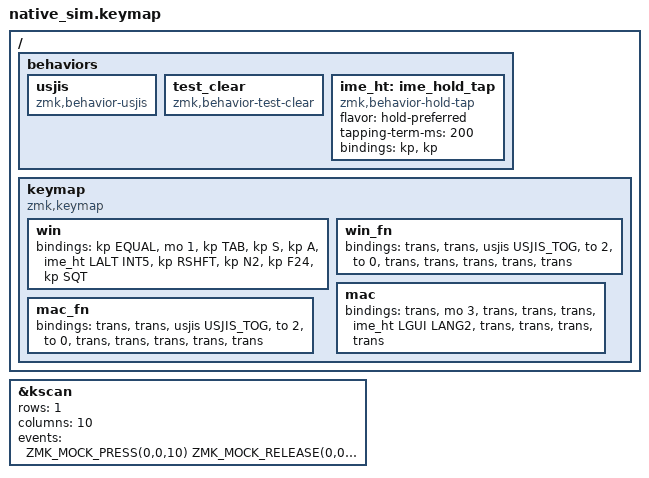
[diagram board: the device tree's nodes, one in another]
/* Generated by tests/zmk/generate.py; do not edit. */
#include <dt-bindings/zmk/keys.h>
#include <behaviors.dtsi>
#include <dt-bindings/zmk/kscan_mock.h>
#include <dt-bindings/zmk/usjis.h>

&kscan {
    rows = <1>;
    columns = <10>;
    events = <
        ZMK_MOCK_PRESS(0,0,10)
        ZMK_MOCK_RELEASE(0,0,10)
        ZMK_MOCK_PRESS(0,1,10)
        ZMK_MOCK_PRESS(0,2,10)
        ZMK_MOCK_RELEASE(0,2,10)
        ZMK_MOCK_RELEASE(0,1,10)
        ZMK_MOCK_PRESS(0,0,10)
        ZMK_MOCK_RELEASE(0,0,10)
        ZMK_MOCK_PRESS(0,6,10)
        ZMK_MOCK_PRESS(0,7,10)
        ZMK_MOCK_RELEASE(0,7,10)
        ZMK_MOCK_RELEASE(0,6,10)
        ZMK_MOCK_PRESS(0,8,10)
        ZMK_MOCK_RELEASE(0,8,10)
        ZMK_MOCK_PRESS(0,1,10)
        ZMK_MOCK_PRESS(0,3,10)
        ZMK_MOCK_RELEASE(0,3,10)
        ZMK_MOCK_RELEASE(0,1,10)
        ZMK_MOCK_PRESS(0,0,10)
        ZMK_MOCK_RELEASE(0,0,10)
        ZMK_MOCK_PRESS(0,6,10)
        ZMK_MOCK_PRESS(0,7,10)
        ZMK_MOCK_RELEASE(0,7,10)
        ZMK_MOCK_RELEASE(0,6,10)
        ZMK_MOCK_PRESS(0,9,10)
        ZMK_MOCK_RELEASE(0,9,10)
        ZMK_MOCK_PRESS(0,8,10)
        ZMK_MOCK_RELEASE(0,8,10)
        ZMK_MOCK_PRESS(0,1,10)
        ZMK_MOCK_PRESS(0,2,10)
        ZMK_MOCK_RELEASE(0,2,10)
        ZMK_MOCK_RELEASE(0,1,10)
        ZMK_MOCK_PRESS(0,0,10)
        ZMK_MOCK_RELEASE(0,0,10)
        ZMK_MOCK_PRESS(0,1,10)
        ZMK_MOCK_PRESS(0,2,10)
        ZMK_MOCK_RELEASE(0,2,10)
        ZMK_MOCK_RELEASE(0,1,10)
        ZMK_MOCK_PRESS(0,0,10)
        ZMK_MOCK_RELEASE(0,0,10)
        ZMK_MOCK_PRESS(0,5,10)
        ZMK_MOCK_RELEASE(0,5,10)
        ZMK_MOCK_PRESS(0,5,300)
        ZMK_MOCK_RELEASE(0,5,10)
        ZMK_MOCK_PRESS(0,5,10)
        ZMK_MOCK_PRESS(0,0,10)
        ZMK_MOCK_RELEASE(0,0,10)
        ZMK_MOCK_RELEASE(0,5,10)
        ZMK_MOCK_PRESS(0,8,10)
        ZMK_MOCK_RELEASE(0,8,10)
        ZMK_MOCK_PRESS(0,1,10)
        ZMK_MOCK_PRESS(0,4,10)
        ZMK_MOCK_RELEASE(0,4,10)
        ZMK_MOCK_RELEASE(0,1,10)
        ZMK_MOCK_PRESS(0,0,10)
        ZMK_MOCK_RELEASE(0,0,10)
        ZMK_MOCK_PRESS(0,5,10)
        ZMK_MOCK_RELEASE(0,5,10)
        ZMK_MOCK_PRESS(0,5,300)
        ZMK_MOCK_RELEASE(0,5,10)
        ZMK_MOCK_PRESS(0,5,10)
        ZMK_MOCK_PRESS(0,0,10)
        ZMK_MOCK_RELEASE(0,0,10)
        ZMK_MOCK_RELEASE(0,5,10)
        ZMK_MOCK_PRESS(0,8,10)
        ZMK_MOCK_RELEASE(0,8,10)
        ZMK_MOCK_PRESS(0,0,10)
        ZMK_MOCK_PRESS(0,1,10)
        ZMK_MOCK_PRESS(0,3,10)
        ZMK_MOCK_RELEASE(0,3,10)
        ZMK_MOCK_RELEASE(0,1,10)
        ZMK_MOCK_PRESS(0,6,10)
        ZMK_MOCK_PRESS(0,7,10)
        ZMK_MOCK_RELEASE(0,7,10)
        ZMK_MOCK_RELEASE(0,6,10)
        ZMK_MOCK_RELEASE(0,0,10)
        ZMK_MOCK_PRESS(0,0,10)
        ZMK_MOCK_RELEASE(0,0,10)
        ZMK_MOCK_PRESS(0,8,10)
        ZMK_MOCK_RELEASE(0,8,10)
        ZMK_MOCK_PRESS(0,0,10)
        ZMK_MOCK_PRESS(0,1,10)
        ZMK_MOCK_PRESS(0,4,10)
        ZMK_MOCK_RELEASE(0,4,10)
        ZMK_MOCK_RELEASE(0,1,10)
        ZMK_MOCK_RELEASE(0,0,10)
        ZMK_MOCK_PRESS(0,0,10)
        ZMK_MOCK_RELEASE(0,0,10)
        ZMK_MOCK_PRESS(0,8,10)
        ZMK_MOCK_RELEASE(0,8,10)
        ZMK_MOCK_PRESS(0,0,10)
        ZMK_MOCK_PRESS(0,1,10)
        ZMK_MOCK_PRESS(0,3,10)
        ZMK_MOCK_RELEASE(0,3,10)
        ZMK_MOCK_RELEASE(0,1,10)
        ZMK_MOCK_PRESS(0,9,10)
        ZMK_MOCK_PRESS(0,1,10)
        ZMK_MOCK_PRESS(0,4,10)
        ZMK_MOCK_RELEASE(0,4,10)
        ZMK_MOCK_RELEASE(0,1,10)
        ZMK_MOCK_RELEASE(0,9,10)
        ZMK_MOCK_RELEASE(0,0,10)
        ZMK_MOCK_PRESS(0,8,10)
        ZMK_MOCK_RELEASE(0,8,10)
        ZMK_MOCK_PRESS(0,1,10)
        ZMK_MOCK_PRESS(0,3,10)
        ZMK_MOCK_RELEASE(0,3,10)
        ZMK_MOCK_RELEASE(0,1,10)
        ZMK_MOCK_PRESS(0,4,10)
        ZMK_MOCK_PRESS(0,1,10)
        ZMK_MOCK_PRESS(0,2,10)
        ZMK_MOCK_RELEASE(0,2,10)
        ZMK_MOCK_RELEASE(0,1,10)
        ZMK_MOCK_RELEASE(0,4,10)
        ZMK_MOCK_PRESS(0,1,10)
        ZMK_MOCK_PRESS(0,4,10)
        ZMK_MOCK_RELEASE(0,4,10)
        ZMK_MOCK_RELEASE(0,1,10)
        ZMK_MOCK_PRESS(0,0,10)
        ZMK_MOCK_RELEASE(0,0,10)
    >;
};

/ {
    behaviors {
        usjis: usjis {
            compatible = "zmk,behavior-usjis";
            #binding-cells = <1>;
        };
        test_clear: test_clear {
            compatible = "zmk,behavior-test-clear";
            #binding-cells = <0>;
        };
    };
};

/ {
    behaviors {
        ime_ht: ime_hold_tap {
            compatible = "zmk,behavior-hold-tap";
            #binding-cells = <2>;
            flavor = "hold-preferred";
            tapping-term-ms = <200>;
            bindings = <&kp>, <&kp>;
        };
    };

    /* The V75 Pro's layers: 0 Win (base), 1 Win Fn, 2 Mac, 3 Mac Fn. Fn+S
     * (&to 2) turns the Mac layer on, Fn+A (&to 0) off; Fn+Tab toggles the
     * mode on both Fn layers; the exclude mask 0x0c keeps the Mac layers
     * identity. */
    keymap {
        compatible = "zmk,keymap";
        win {
            bindings = <&kp EQUAL &mo 1 &kp TAB &kp S &kp A &ime_ht LALT INT5 &kp RSHFT &kp N2 &kp F24 &kp SQT>;
        };
        win_fn {
            bindings = <&trans &trans &usjis USJIS_TOG &to 2 &to 0 &trans &trans &trans &trans &trans>;
        };
        mac {
            bindings = <&trans &mo 3 &trans &trans &trans &ime_ht LGUI LANG2 &trans &trans &trans &trans>;
        };
        mac_fn {
            bindings = <&trans &trans &usjis USJIS_TOG &to 2 &to 0 &trans &trans &trans &trans &trans>;
        };
    };
};
